# psoc4200ds register map
Vendor: Cypress Semiconductor; Series: PSoC4200DS; File version: 1.0
CPU: CM0 r0p1, little endian, no MPU, no FPU, 2 interrupt priority bits
Registers are 32-bit, read-write, reset 0x0 unless marked. A register's access mark holds for its fields unless they carry their own. Offsets are from the block's base; lines under a group give offsets from that group; [hi:lo] are bit positions; {n}, {i} and the like mark numbered series; 'fields as' and 'values as' point back to an identical list; <NAME> marks a mode.

## Memory map
0x40010000 PERI size 0x10000 — Peripheral Interconnect
0x40020000 HSIOM size 0x4000 — High Speed IO Matrix (HSIOM)
0x40030000 SRSSLT size 0x10000 — System Resources Lite Subsystem
0x40040000 GPIO size 0x4000 — GPIO port control/configuration
0x40050000 PRGIO size 0x1000 — Programmable IO configuration
0x40060000 SCB0 size 0x10000 — Serial Communications Block (SPI/UART/I2C)
0x40070000 SCB1 size 0x10000
0x40080000 SCB2 size 0x10000
0x400A0000 TCPWM size 0x10000 — Timer/Counter/PWM
0x400B0000 LPCOMP size 0x10000 — Low Power Comparators
0x40100000 CPUSS size 0x1000 — CPU Subsystem
0x40101000 DMAC size 0x1000 — DataWire/DMA Controller
0x40110000 SPCIF size 0x10000 — Flash Control Interface

## Interrupts
0 ioss_interrupts_gpio_0 (CPUSS) — GPIO P0
1 ioss_interrupts_gpio_1 (CPUSS) — GPIO P1
2 ioss_interrupts_gpio_2 (CPUSS) — GPIO P2
3 ioss_interrupts_gpio_3 (CPUSS) — GPIO P3
4 ioss_interrupt_gpio (CPUSS) — GPIO All Ports
5 lpcomp_interrupt (CPUSS) — LPCOMP trigger interrupt
6 srss_interrupt_wdt (CPUSS) — WDT
7 scb_0_interrupt (CPUSS) — SCB #0
8 scb_1_interrupt (CPUSS) — SCB #1
9 scb_2_interrupt (CPUSS) — SCB #2
10 cpuss_interrupt_dma (CPUSS) — DMA Interrupt
11 cpuss_interrupt_spcif (CPUSS) — SPCIF interrupt
12 tcpwm_interrupts_0 (CPUSS) — TCPWM #0, Counter #0
13 tcpwm_interrupts_1 (CPUSS) — TCPWM #0, Counter #1
14 tcpwm_interrupts_2 (CPUSS) — TCPWM #0, Counter #2
15 tcpwm_interrupts_3 (CPUSS) — TCPWM #0, Counter #3
16 udb_interrupts_0 (CPUSS)
17 udb_interrupts_1 (CPUSS)
18 udb_interrupts_2 (CPUSS)
19 udb_interrupts_3 (CPUSS)
20 udb_interrupts_4 (CPUSS)
21 udb_interrupts_5 (CPUSS)
22 udb_interrupts_6 (CPUSS)
23 udb_interrupts_7 (CPUSS)
24 udb_interrupts_0 (CPUSS)
25 udb_interrupts_1 (CPUSS)
26 udb_interrupts_2 (CPUSS)
27 udb_interrupts_3 (CPUSS)
28 udb_interrupts_4 (CPUSS)
29 udb_interrupts_5 (CPUSS)
30 udb_interrupts_6 (CPUSS)
31 udb_interrupts_7 (CPUSS)

## HSIOM — High Speed IO Matrix (HSIOM)
Base 0x40020000
{0x0+0x100*i} PRT[{i}] (i=0..3) group — HSIOM port registers
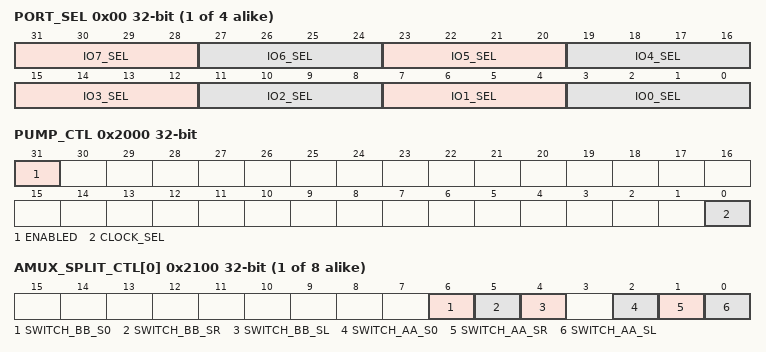
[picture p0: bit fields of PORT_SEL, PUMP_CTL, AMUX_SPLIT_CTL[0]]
  0x00 PORT_SEL — Port selection register
    [4n+3:4n] IO{n}_SEL (n=1..7) — Selects connection for IO pad {n} route.
    [3:0] IO0_SEL — Selects connection for IO pad 0 route.
      0=GPIO (SW controlled GPIO.); 1=GPIO_DSI (SW controlled 'out', DSI controlled 'oe_n'.); 2=DSI_DSI (DSI controlled 'out' and 'oe_n'.); 3=DSI_GPIO (DSI controlled 'out', SW controlled 'oe_n'.); 4=CSD_SENSE (CSD sense connection (analog mode)); 5=CSD_SHIELD (CSD shield connection (analog mode)); 6=AMUXA (AMUXBUS A connection.); 7=AMUXB (AMUXBUS B connection. This mode is also used for CSD GPIO charging. When CSD GPIO charging is enabled in CSD_CONTROL, 'oe_n' is connected to '!csd_charge' signal (and IO pad is also still connected to AMUXBUS B).); {v}=ACT_{v-8} (Chip specific Active source {v-8} connection.) (v=8..11); 12=LCD_COM (LCD common connection. This mode provides DeepSleep functionality (provided that the LCD block is enabled and properly configured).); 13=LCD_SEG (LCD segment connection. This mode provides DeepSleep functionality (provided that the LCD block is enabled and properly configured).); 14=DS_2 (Chip specific DeepSleep source 2 connection.); 15=DS_3 (Chip specific DeepSleep source 3 connection.)
0x2000 PUMP_CTL — Pump control
  [31] ENABLED — Pump enabled: '0': Disabled. '1': Enabled.
  [0] CLOCK_SEL — Clock select: '0': External clock. '1': Internal clock (deprecated).
{0x2100+4i} AMUX_SPLIT_CTL[{i}] (i=0..7) — AMUX splitter cell control
  [6] SWITCH_BB_S0 — T-switch control for AMUXBUSB vssa/ground switch.
  [5] SWITCH_BB_SR — T-switch control for Right AMUXBUSB switch.
  [4] SWITCH_BB_SL — T-switch control for Left AMUXBUSB switch.
  [2] SWITCH_AA_S0 — T-switch control for AMUXBUSA vssa/ground switch: '0': switch open. '1': switch closed.
  [1] SWITCH_AA_SR — T-switch control for Right AMUXBUSA switch: '0': switch open. '1': switch closed.
  [0] SWITCH_AA_SL — T-switch control for Left AMUXBUSA switch: '0': switch open. '1': switch closed.

## Licence text in the file
Copyright 2016-2020 Cypress Semiconductor Corporation. SPDX-License-Identifier: Apache-2.0 . Licensed under the Apache License, Version 2.0 (the "License"); you may not use this file except in compliance with the License. You may obtain a copy of the License at http://www.apache.org/licenses/LICENSE-2.0 . Unless required by applicable law or agreed to in writing, software distributed under the License is distributed on an "AS IS" BASIS, WITHOUT WARRANTIES OR CONDITIONS OF ANY KIND, either express or implied. See the License for the specific language governing permissions and limitations under the License.
